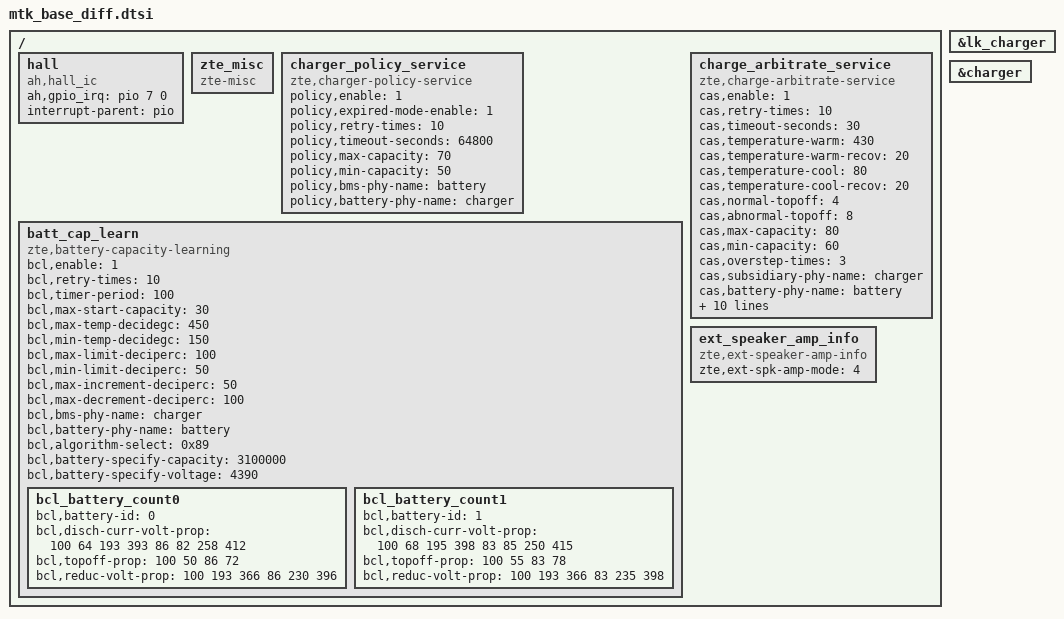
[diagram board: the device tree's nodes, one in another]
/*
 * when you want to delete some nodes or property, modify the dtsi.
 * some diff between mtk and zte apollo.
 */

/{
	hall: hall {
		compatible = "ah,hall_ic";
		status="okay";
		ah,gpio_irq = <&pio 7 0>;
		interrupt-parent = <&pio>;
	};

	zte_misc: zte_misc {
		status="okay";
		compatible = "zte-misc";
	};

	charger_policy_service {
		compatible = "zte,charger-policy-service";
		status="okay";
		policy,enable = <1>;
		policy,expired-mode-enable = <1>;
		policy,retry-times = <10>;
		policy,timeout-seconds = <64800>;/* 18 hours */
		policy,max-capacity = <70>;
		policy,min-capacity = <50>;
		policy,bms-phy-name = "battery";
		policy,battery-phy-name = "charger";
	};

	batt_cap_learn {
		compatible = "zte,battery-capacity-learning";
		bcl,enable = <1>;
		bcl,retry-times = <10>;
		bcl,timer-period = <100>;/*ms*/
		bcl,max-start-capacity = <30>;
		bcl,max-temp-decidegc = <450>;
		bcl,min-temp-decidegc = <150>;
		bcl,max-limit-deciperc = <100>;
		bcl,min-limit-deciperc = <50>;
		bcl,max-increment-deciperc = <50>;
		bcl,max-decrement-deciperc = <100>;
		bcl,bms-phy-name = "charger";
		bcl,battery-phy-name = "battery";
		/*bit7: 0: use zte algorithm calc age; 1: use platform algorithm calc age*/
		/*bit4: enable zte algorithm*/
		/*bit3: enable platform algorithm*/
		/*bit0: platform algorithm mode 0: integral mode; 1: delta mode*/
		bcl,algorithm-select = <0x89>;
		bcl,battery-specify-capacity = <3100000>;
		bcl,battery-specify-voltage = <4390>;

		bcl_battery_count0 {
			bcl,battery-id = <0>;

			/*3.4V-3.0V 0.2C delta capacity*/
			/*age 150ma 768ma(0.2C) 1300ma*/
			bcl,disch-curr-volt-prop = <100 64 193 393
							86 82 258 412>;

			/*current: 0.04C - 0.02C delta*/
			bcl,topoff-prop = <100 50
					86 72 >;

			/*reduc voltage  50mv 100mv*/
			bcl,reduc-volt-prop = <100 193 366
						86 230 396 >;
		};

		bcl_battery_count1 {
			bcl,battery-id = <1>;

			/*age 150ma 768ma(0.2C) 1300ma*/
			bcl,disch-curr-volt-prop = <100 68 195 398
							83 85 250 415>;

			/*current: 0.04C - 0.02C delta*/
			bcl,topoff-prop = <100 55
					83 78 >;

			/*reduc voltage  50mv 100mv*/
			bcl,reduc-volt-prop = <100 193 366
						83 235 398 >;
		};
	};

	charge_arbitrate_service {
		compatible = "zte,charge-arbitrate-service";
		cas,enable = <1>;
		cas,retry-times = <10>;
		cas,timeout-seconds = <30>;/*s*/
		cas,temperature-warm = <430>;
		cas,temperature-warm-recov = <20>;
		cas,temperature-cool = <80>;
		cas,temperature-cool-recov = <20>;
		cas,normal-topoff = <4>;
		cas,abnormal-topoff = <8>;
		cas,max-capacity = <80>;
		cas,min-capacity = <60>;
		cas,overstep-times = <3>;
		cas,subsidiary-phy-name = "charger";
		cas,battery-phy-name = "battery";
		cas,bcl-phy-name = "bcl";
		cas,fcv-phy = "interface";
		cas,fcc-phy = "interface";
		cas,icl-phy = "interface";
		cas,topoff-phy = "interface";
		cas,recharge-soc-phy = "interface";
		cas,recharge-voltage-phy = "interface";
		cas,voltage-cc-cv-phy = "interface";
		/* age, fcv, fcc, rech_soc_1st, rech_soc_2st rech_vol_1st, rech_vol_2st **/
		cas,age-data = <100 4400000 2000000 0 0 100 200
				95 4380000 1900000 0 0 150 250
				90 4360000 1800000 0 0 200 300
				85 4340000 1700000 0 0 250 350
				80 4320000 1600000 0 0 300 400
				75 4300000 1550000 0 0 350 450>;
	};

	ext_speaker_amp_info {
		status="okay";
		compatible = "zte,ext-speaker-amp-info";
		zte,ext-spk-amp-mode = <4>;
	};
};

&lk_charger {
	/delete-property/ enable_pe_plus;
};

&charger {
	/delete-property/ enable_pe_plus;
	/delete-property/ enable_pe_2;
	/delete-property/ enable_pe_3;
	/delete-property/ enable_pe_4;
};
